# ADC10_A_1 register map
Vendor: Texas Instruments
Peripheral module from a debugger description file (folder msp430).
Registers are 16-bit, read-write, reset 0x0 unless marked. A register's access mark holds for its fields unless they carry their own. Offsets are as the file gives them; lines under a group give offsets from that group; [hi:lo] are bit positions; {n}, {i} and the like mark numbered series; 'fields as' and 'values as' point back to an identical list; <NAME> marks a mode.

## ADC10_A
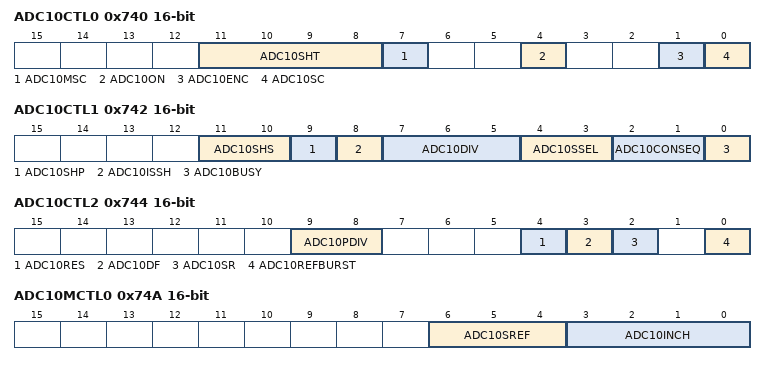
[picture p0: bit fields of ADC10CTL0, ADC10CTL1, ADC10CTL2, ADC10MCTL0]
0x740 ADC10CTL0 — ADC10 Control 0
  [11:8] ADC10SHT — ADC10 Sample Hold Select Bit: 0
    {v}=ADC10 Sample Hold Select {v} (v=0..15)
  [7] ADC10MSC — ADC10 Multiple SampleConversion
  [4] ADC10ON — ADC10 On/enable
  [1] ADC10ENC — ADC10 Enable Conversion
  [0] ADC10SC — ADC10 Start Conversion
0x742 ADC10CTL1 — ADC10 Control 1
  [11:10] ADC10SHS — ADC10 Sample/Hold Source 0
    {v}=ADC10 Sample/Hold Source: {v} (v=0..3)
  [9] ADC10SHP — ADC10 Sample/Hold Pulse Mode
  [8] ADC10ISSH — ADC10 Invert Sample Hold Signal
  [7:5] ADC10DIV — ADC10 Clock Divider Select 0
    {v}=ADC10 Clock Divider Select: {v} (v=0..7)
  [4:3] ADC10SSEL — ADC10 Clock Source Select 0
    {v}=ADC10 Clock Source Select: {v} (v=0..3)
  [2:1] ADC10CONSEQ — ADC10 Conversion Sequence Select 0
    {v}=ADC10 Conversion Sequence Select: {v} (v=0..3)
  [0] ADC10BUSY
0x744 ADC10CTL2 — ADC10 Control 2
  [9:8] ADC10PDIV — ADC10 predivider Bit: 0
    0=ADC10 predivider /1; 1=ADC10 predivider /2; 2=ADC10 predivider /64; 3=ADC10 predivider reserved
  [4] ADC10RES — ADC10 Resolution Bit
  [3] ADC10DF — ADC10 Data Format
  [2] ADC10SR — ADC10 Sampling Rate
  [0] ADC10REFBURST — ADC10 Reference Burst
0x746 ADC10LO access not given reset not defined — ADC10 Window Comparator High Threshold
0x748 ADC10HI access not given reset not defined — ADC10 Window Comparator High Threshold
0x74A ADC10MCTL0 — ADC10 Memory Control 0
  [6:4] ADC10SREF — ADC10 Select Reference Bit 0
    {v}=ADC10 Select Reference {v} (v=0..7)
  [3:0] ADC10INCH — ADC10 Input Channel Select Bit 0
    {v}=ADC10 Input Channel {v} (v=0..15)
0x752 ADC10MEM0 access not given reset not defined — ADC10 Conversion Memory 0
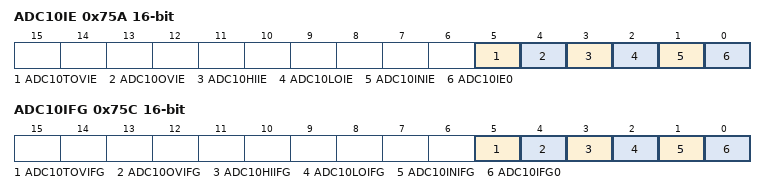
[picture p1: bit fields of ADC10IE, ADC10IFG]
0x75A ADC10IE — ADC10 Interrupt Enable
  [5] ADC10TOVIE — ADC10_A conversion-time-overflow Interrupt enable
  [4] ADC10OVIE — ADC10_A ADC10MEM overflow Interrupt enable
  [3] ADC10HIIE — ADC10_A Interrupt enable for upper threshold of the Window comparator
  [2] ADC10LOIE — ADC10_A Interrupt enable for lower threshold of the Window comparator
  [1] ADC10INIE — ADC10_A Interrupt enable for the inside of window of the Window comparator
  [0] ADC10IE0 — ADC10_A Interrupt enable
0x75C ADC10IFG — ADC10 Interrupt Flag
  [5] ADC10TOVIFG — ADC10_A conversion-time-overflow Interrupt Flag
  [4] ADC10OVIFG — ADC10_A ADC10MEM overflow Interrupt Flag
  [3] ADC10HIIFG — ADC10_A Interrupt Flag for upper threshold of the Window comparator
  [2] ADC10LOIFG — ADC10_A Interrupt Flag for lower threshold of the Window comparator
  [1] ADC10INIFG — ADC10_A Interrupt Flag for the inside of window of the Window comparator
  [0] ADC10IFG0 — ADC10_A Interrupt Flag
0x75E ADC10IV access not given reset not defined — ADC10 Interrupt Vector Word
